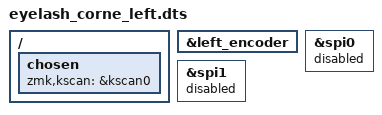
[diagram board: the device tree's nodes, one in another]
/dts-v1/;

/* SoC */
#include <nordic/nrf52840_qiaa.dtsi>

/* Shared keyboard defs */
#include "eyelash_corne.dtsi"

 / {
    chosen {
        zmk,kscan = &kscan0;
    };
 };

&left_encoder {
    status = "okay";
};

/* Disable ALL SPI on left half */
&spi0 {
    status = "disabled";
};

&spi1 {
    status = "disabled";
};


